# HK32L0xx register map
Vendor: HKMicroChip Ltd.; Series: HK32L0xx; File version: 1.3
CPU: CM0 r0p0, little endian, no MPU, no FPU, 3 interrupt priority bits
Registers are 32-bit, read-write, reset 0x0 unless marked. A register's access mark holds for its fields unless they carry their own. Offsets are from the block's base; [hi:lo] are bit positions.

## RCC
Base 0x40021000
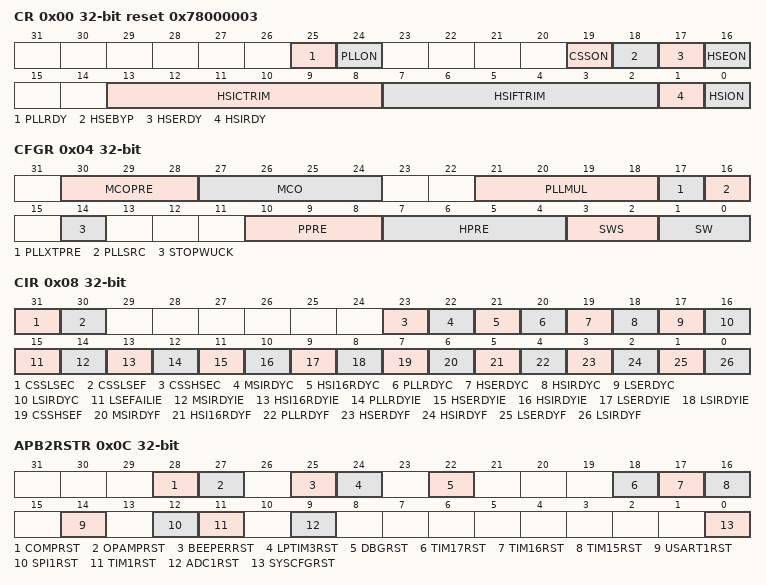
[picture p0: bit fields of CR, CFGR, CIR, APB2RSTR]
0x00 CR access per field reset 0x78000003
  [25] PLLRDY ro — PLL clock ready flag
  [24] PLLON rw — PLL enable
  [19] CSSON rw — Clock security system enable
  [18] HSEBYP rw — HSE crystal oscillator bypass
  [17] HSERDY ro — HSE clock ready flag
  [16] HSEON rw — HSE clock enable
  [13:8] HSICTRIM rw — HSI clock calibration
  [7:2] HSIFTRIM rw — HSI clock trimming
  [1] HSIRDY ro — HSI clock ready flag
  [0] HSION rw — HSI clock enable
0x04 CFGR access per field
  [30:28] MCOPRE rw — Microcontroller clock output prescaler
  [27:24] MCO rw — Microcontroller clock output
  [21:18] PLLMUL rw — PLL multiplication factor
  [17] PLLXTPRE rw — HSE divider for PLL input clock
  [16] PLLSRC rw — PLL input clock source
  [14] STOPWUCK rw — Stop wake up SYSCLK selection
  [10:8] PPRE rw — PCLK prescaler
  [7:4] HPRE rw — HCLK prescaler factor
  [3:2] SWS ro — System clock switch status
  [1:0] SW rw — System clock switch
0x08 CIR access per field
  [31] CSSLSEC wo — Clock security system LSE interrupt flag clear
  [30] CSSLSEF ro — Clock security system fail
  [23] CSSHSEC wo — Clock security system HSE interrupt flag clear
  [22] MSIRDYC wo — MSI ready interrupt clear
  [21] HSI16RDYC wo — HSI16 ready Interrupt clear
  [20] PLLRDYC wo — PLL ready interrupt clear
  [19] HSERDYC wo — HSE ready interrupt clear
  [18] HSIRDYC wo — HSI ready interrupt clear
  [17] LSERDYC wo — LSE ready interrupt clear
  [16] LSIRDYC wo — LSI ready interrupt clear
  [15] LSEFAILIE rw — LSE fail interrupt enable
  [14] MSIRDYIE rw — MSI ready interrupt enable
  [13] HSI16RDYIE rw — HSI16 ready interrupt enable
  [12] PLLRDYIE rw — PLL ready interrupt enable
  [11] HSERDYIE rw — HSE ready interrupt enable
  [10] HSIRDYIE rw — HSI ready interrupt enable
  [9] LSERDYIE rw — LSE ready interrupt enable
  [8] LSIRDYIE rw — LSI ready interrupt enable
  [7] CSSHSEF ro — Clock security system HSE interrupt flag
  [6] MSIRDYF ro — MSI ready interrupt flag
  [5] HSI16RDYF ro — HSI16 ready interrupt flag
  [4] PLLRDYF ro — PLL ready interrupt flag
  [3] HSERDYF ro — HSE ready interrupt flag
  [2] HSIRDYF ro — HSI ready interrupt flag
  [1] LSERDYF ro — LSE ready interrupt flag
  [0] LSIRDYF ro — LSI ready interrupt flag
0x0C APB2RSTR
  [28] COMPRST — Comparator reset
  [27] OPAMPRST — OAMP reset
  [25] BEEPERRST — BEEPER reset
  [24] LPTIM3RST — LPTIM3 reset
  [22] DBGRST — DBG reset
  [18] TIM17RST — Reset TIM17
  [17] TIM16RST — Reset TIM16
  [16] TIM15RST — Reset TIM15
  [14] USART1RST — Reset USART1
  [12] SPI1RST — Reset SPI1
  [11] TIM1RST — Reset TIM1
  [9] ADC1RST — Reset ADC interface
  [0] SYSCFGRST — Reset SYSCFG
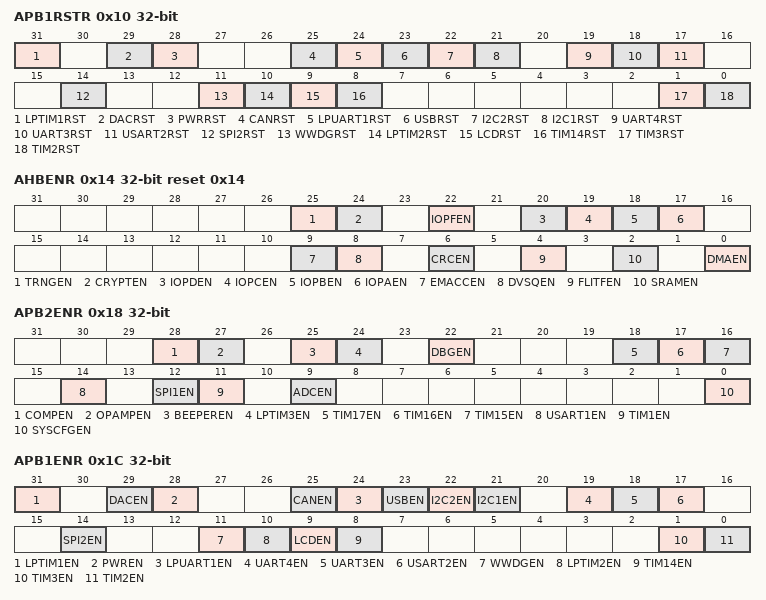
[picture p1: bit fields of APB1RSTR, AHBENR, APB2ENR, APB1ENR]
0x10 APB1RSTR
  [31] LPTIM1RST — Reset LPTIM1
  [29] DACRST — Reset DAC interface
  [28] PWRRST — Reset Power interface
  [25] CANRST — Reset CAN
  [24] LPUART1RST — Reset LPUART1
  [23] USBRST — Reset USB
  [22] I2C2RST — Reset I2C2
  [21] I2C1RST — Reset I2C1
  [19] UART4RST — Reset UART4
  [18] UART3RST — Reset UART3
  [17] USART2RST — Reset USART2
  [14] SPI2RST — Reset SPI2
  [11] WWDGRST — Reset WWDG
  [10] LPTIM2RST — Reset LPTIM2
  [9] LCDRST — Reset LCD
  [8] TIM14RST — Reset TIM14
  [1] TIM3RST — Reset TIM3
  [0] TIM2RST — Reset TIM2
0x14 AHBENR reset 0x14
  [25] TRNGEN — True Random Number Generator clock enable
  [24] CRYPTEN — Crypto clock enable
  [22] IOPFEN — I/O port F clock enable
  [20] IOPDEN — I/O port D clock enable
  [19] IOPCEN — I/O port C clock enable
  [18] IOPBEN — I/O port B clock enable
  [17] IOPAEN — I/O port A clock enable
  [9] EMACCEN — EMACC clock enable
  [8] DVSQEN — DVSQ clock enable
  [6] CRCEN — CRC clock enable
  [4] FLITFEN — FLITF clock enable
  [2] SRAMEN — SRAM interface clock enable
  [0] DMAEN — DMA clock enable
0x18 APB2ENR
  [28] COMPEN — Comparator Control Module clock enable
  [27] OPAMPEN — OAMP clock enable
  [25] BEEPEREN — Beeper clock enable
  [24] LPTIM3EN — LPTIM3 clock enable
  [22] DBGEN — DBG clock enable
  [18] TIM17EN — TIM17 clock enable
  [17] TIM16EN — TIM16 clock enable
  [16] TIM15EN — TIM15 clock enable
  [14] USART1EN — USART1 clock enable
  [12] SPI1EN — SPI1 clock enable
  [11] TIM1EN — TIM1 clock enable
  [9] ADCEN — ADC clock enable
  [0] SYSCFGEN — System control configuration clock enable
0x1C APB1ENR
  [31] LPTIM1EN — Low-power timer1 clock enable
  [29] DACEN — DAC interface clock enable
  [28] PWREN — Power interface clock enable
  [25] CANEN — CAN clock enable
  [24] LPUART1EN — LPUART1 clock enable
  [23] USBEN — USB clock enable
  [22] I2C2EN — I2C2 clock enable
  [21] I2C1EN — I2C1 clock enable
  [19] UART4EN — UART4 clock enable
  [18] UART3EN — UART3 clock enable
  [17] USART2EN — USART2 clock enable
  [14] SPI2EN — SPI2 clock enable
  [11] WWDGEN — WWDG clock enable
  [10] LPTIM2EN — LPTIM2 clock enable
  [9] LCDEN — LCD clock enable
  [8] TIM14EN — TIM14 clock enable
  [1] TIM3EN — TIM3 clock enable
  [0] TIM2EN — TIM2 clock enable
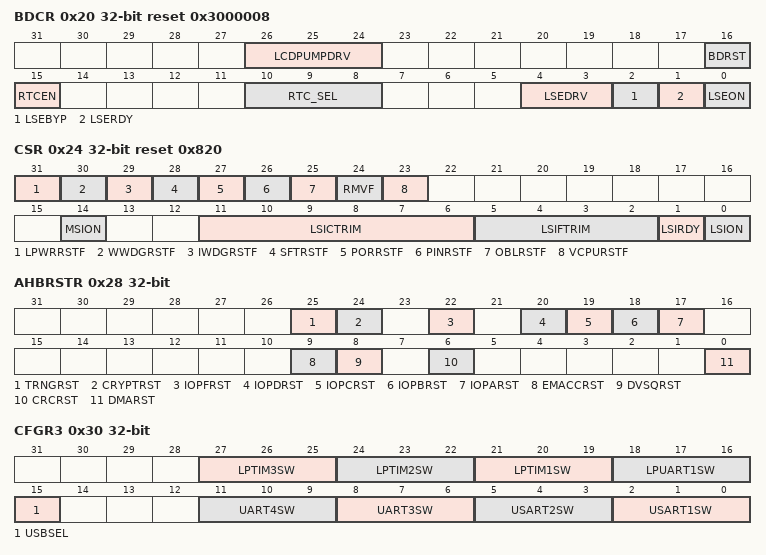
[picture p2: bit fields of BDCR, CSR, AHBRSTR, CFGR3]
0x20 BDCR access per field reset 0x3000008
  [26:24] LCDPUMPDRV rw — LCD PUMP driver capability selection
  [16] BDRST rw — Backup domain software reset
  [15] RTCEN rw — RTC clock enable
  [10:8] RTC_SEL rw — RTC clock source selection
  [4:3] LSEDRV rw — LSE oscillator drive capability
  [2] LSEBYP rw — LSE oscillator bypass
  [1] LSERDY ro — LSE oscillator ready
  [0] LSEON rw — LSE oscillator enable
0x24 CSR access per field reset 0x820
  [31] LPWRRSTF ro — Low-power reset flag
  [30] WWDGRSTF ro — Window watchdog reset flag
  [29] IWDGRSTF ro — Independent watchdog reset flag
  [28] SFTRSTF ro — Software reset flag
  [27] PORRSTF ro — POR/PDR reset flag
  [26] PINRSTF ro — NRST pin reset flag
  [25] OBLRSTF ro — Option byte loader reset flag
  [24] RMVF rw — Remove reset flag
  [23] VCPURSTF ro — Reset flag of the VCore domain
  [14] MSION rw — MSI clock enable
  [11:6] LSICTRIM rw — LSI clock calibration
  [5:2] LSIFTRIM rw — LSI clock trimming
  [1] LSIRDY ro — LSI oscillator ready
  [0] LSION rw — LSI oscillator enable
0x28 AHBRSTR
  [25] TRNGRST — True Random Number Generator module reset
  [24] CRYPTRST — encryption module reset
  [22] IOPFRST — Reset I/O port F
  [20] IOPDRST — Reset I/O port D
  [19] IOPCRST — Reset I/O port C
  [18] IOPBRST — Reset I/O port B
  [17] IOPARST — Reset I/O port A
  [9] EMACCRST — Reset EMACC
  [8] DVSQRST — DVSQ reset
  [6] CRCRST — Reset CRC
  [0] DMARST — Reset DMA
0x2C CFGR2
  [3:0] PREDIV — PREDIV division factor
0x30 CFGR3
  [27:25] LPTIM3SW — LPTIM3 clock source selection
  [24:22] LPTIM2SW — LPTIM2 clock source selection
  [21:19] LPTIM1SW — LPTIM1 clock source selection
  [18:16] LPUART1SW — LPUART1clock source selection
  [15] USBSEL — USB clock source selection
  [11:9] UART4SW — UART4 clock source selection
  [8:6] UART3SW — UART3 clock source selection
  [5:3] USART2SW — USART2 clock source selection
  [2:0] USART1SW — USART1 clock source selection
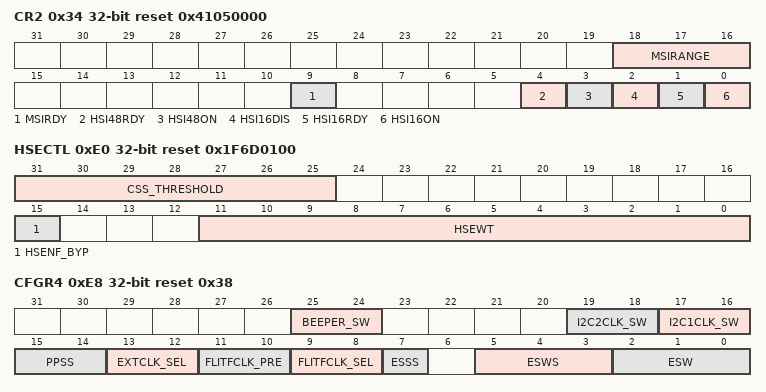
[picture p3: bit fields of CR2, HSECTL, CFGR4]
0x34 CR2 access per field reset 0x41050000
  [18:16] MSIRANGE rw — MSI frequency selection
  [9] MSIRDY ro — MSI clock ready flag
  [4] HSI48RDY ro — HSI48 clock ready flag
  [3] HSI48ON rw — HSI48 clock enable
  [2] HSI16DIS rw — HSI16 clock enable
  [1] HSI16RDY ro — HSI16 clock ready flag
  [0] HSI16ON rw — HSI16 clock enable
0xE0 HSECTL reset 0x1F6D0100
  [31:25] CSS_THRESHOLD — CSS counter threshold control
  [15] HSENF_BYP — HSE noise filter bypass
  [11:0] HSEWT — HSE stabilize wait time setting
0xE4 PLLCTL reset 0x40210A22
  [31:27] PLLWT — PLL stabilize wait time setting
0xE8 CFGR4 access per field reset 0x38
  [25:24] BEEPER_SW rw — BEEPER clock source selection
  [19:18] I2C2CLK_SW rw — I2C2 clock source selection
  [17:16] I2C1CLK_SW rw — I2C1 clock source selection
  [15:14] PPSS rw — Pll PREDIV clock source select
  [13:12] EXTCLK_SEL rw — External GPIO clock pin selection
  [11:10] FLITFCLK_PRE rw — Flash interface clock prescale
  [9:8] FLITFCLK_SEL rw — Flash interface clock selection
  [7] ESSS rw — SYSCLK setting bit selection
  [5:3] ESWS ro — SYSCLK clock source status
  [2:0] ESW rw — SYSCLK clock source selection
